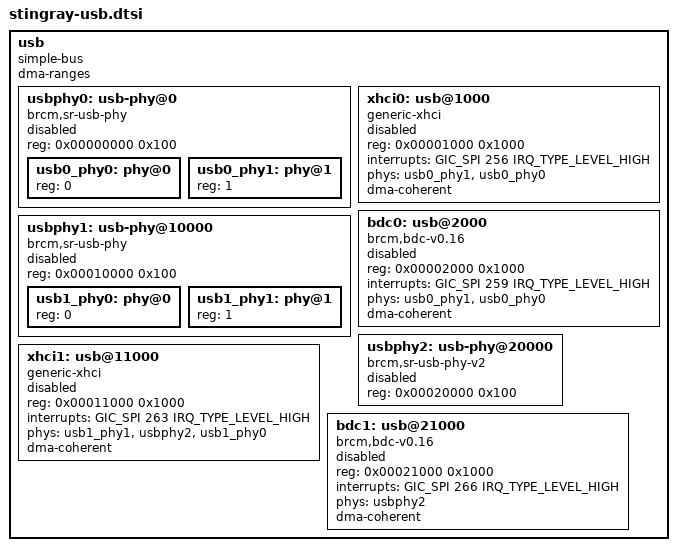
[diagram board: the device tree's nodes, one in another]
// SPDX-License-Identifier: (GPL-2.0 or BSD-3-Clause)
/*
 *Copyright(c) 2018 Broadcom
 */
	usb {
		compatible = "simple-bus";
		dma-ranges;
		#address-cells = <1>;
		#size-cells = <1>;
		ranges = <0x0 0x0 0x68500000 0x00400000>;

		usbphy0: usb-phy@0 {
			compatible = "brcm,sr-usb-phy";
			reg = <0x00000000 0x100>;
			#address-cells = <1>;
			#size-cells = <0>;
			status = "disabled";

			usb0_phy0: phy@0 {
				reg = <0>;
				#phy-cells = <0>;
			};
			usb0_phy1: phy@1 {
				reg = <1>;
				#phy-cells = <0>;
			};

		};

		xhci0: usb@1000 {
			compatible = "generic-xhci";
			reg = <0x00001000 0x1000>;
			interrupts = <GIC_SPI 256 IRQ_TYPE_LEVEL_HIGH>;
			phys = <&usb0_phy1>, <&usb0_phy0>;
			phy-names = "phy0", "phy1";
			dma-coherent;
			status = "disabled";
		};

		bdc0: usb@2000 {
			compatible = "brcm,bdc-v0.16";
			reg = <0x00002000 0x1000>;
			interrupts = <GIC_SPI 259 IRQ_TYPE_LEVEL_HIGH>;
			phys = <&usb0_phy1>, <&usb0_phy0>;
			phy-names = "phy0", "phy1";
			dma-coherent;
			status = "disabled";
		};

		usbphy1: usb-phy@10000 {
			compatible = "brcm,sr-usb-phy";
			reg = <0x00010000 0x100>;
			#address-cells = <1>;
			#size-cells = <0>;
			status = "disabled";

			usb1_phy0: phy@0 {
				reg = <0>;
				#phy-cells = <0>;
			};
			usb1_phy1: phy@1 {
				reg = <1>;
				#phy-cells = <0>;
			};
		};

		usbphy2: usb-phy@20000 {
			compatible = "brcm,sr-usb-phy-v2";
			reg = <0x00020000 0x100>;
			#address-cells = <1>;
			#size-cells = <0>;
			#phy-cells = <0>;
			status = "disabled";
		};

		xhci1: usb@11000 {
			compatible = "generic-xhci";
			reg = <0x00011000 0x1000>;
			interrupts = <GIC_SPI 263 IRQ_TYPE_LEVEL_HIGH>;
			phys = <&usb1_phy1>, <&usbphy2>, <&usb1_phy0>;
			phy-names = "phy0", "phy1", "phy2";
			dma-coherent;
			status = "disabled";
		};

		bdc1: usb@21000 {
			compatible = "brcm,bdc-v0.16";
			reg = <0x00021000 0x1000>;
			interrupts = <GIC_SPI 266 IRQ_TYPE_LEVEL_HIGH>;
			phys = <&usbphy2>;
			phy-names = "phy0";
			dma-coherent;
			status = "disabled";
		};
	};
